# hsm_non_sec_secure register map
Vendor: Texas Instruments
Peripheral module from a debugger description file (folder CC35X1E).
Registers are 32-bit, access per field, reset 0x0 unless marked. A register's access mark holds for its fields unless they carry their own. Offsets are as the file gives them; lines under a group give offsets from that group; [hi:lo] are bit positions; {n}, {i} and the like mark numbered series; 'fields as' and 'values as' point back to an identical list; <NAME> marks a mode.

## hsm_non_sec_secure
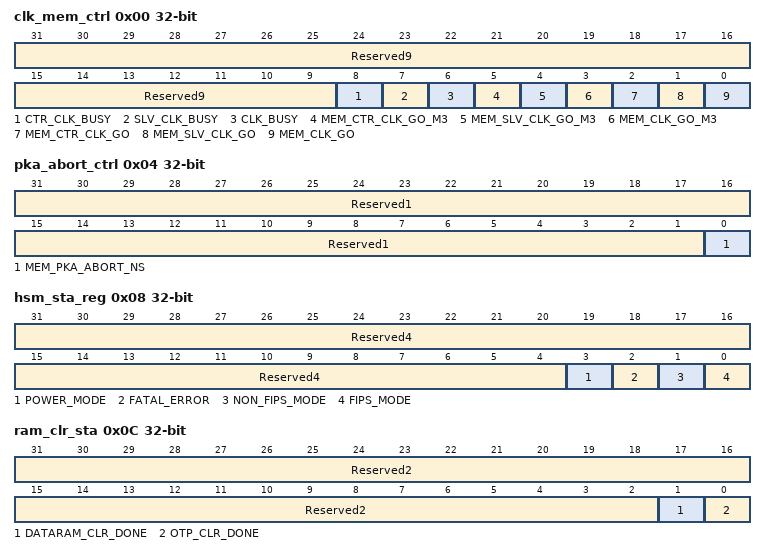
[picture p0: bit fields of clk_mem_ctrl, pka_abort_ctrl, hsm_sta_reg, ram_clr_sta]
0x00 clk_mem_ctrl — This register is used for enabling clock to the module
  [31:9] Reserved9 ro — Reads to this field return zero, writes to this field are ignored.
  [8] CTR_CLK_BUSY ro — When 1b, indicates that the counter clock domain is active. This signal is always asserted (set to '1'), except when the counter module is in reset (ctr_reset_n set to '0').
  [7] SLV_CLK_BUSY ro — When 1b indicates the Host interface is active and busy with Host bus transfers.
  [6] CLK_BUSY ro — when 1b, indicates that the module is active and busy with processing data and tokens.
  [5] MEM_CTR_CLK_GO_M3 rw — Write this bit to enable counter clock
    0=DIS (Write 0b to disable clock); 1=EN (Write 1b to enable clock)
  [4] MEM_SLV_CLK_GO_M3 rw — Write this bit to enable host interface clock
    1=EN (Write 1b to enable clock); 0=DIS (Write 0b to disable clock)
  [3] MEM_CLK_GO_M3 rw — M3 writes this bit to enable clock to the module
    values as MEM_CTR_CLK_GO_M3
  [2] MEM_CTR_CLK_GO rw — Write this bit to enable counter clock
    values as MEM_CTR_CLK_GO_M3
  [1] MEM_SLV_CLK_GO rw — Write this bit to enable host interface clock
    values as MEM_SLV_CLK_GO_M3
  [0] MEM_CLK_GO rw — Write this bit to enable clock to the module
    values as MEM_SLV_CLK_GO_M3
0x04 pka_abort_ctrl — This register is used for aborting PKA operation.
  [31:1] Reserved1 ro — Reads to this field return zero, writes to this field are ignored.
  [0] MEM_PKA_ABORT_NS rw — Write 1 to this bit to abort PKA operation
    1=ABORT (Set to 1, to abort PKA operation)
0x08 hsm_sta_reg ro — This register provides EIP130 status
  [31:4] Reserved4 — Reads to this field return zero, writes to this field are ignored.
  [3] POWER_MODE — Power mode value 1'b1 indicates hsm is in sleep and value 1'b0 indicates hsm is out of sleep.
  [2] FATAL_ERROR — If active (set to 1b), EIP130 detected a fatal error and stops operation. fatal error can happen when CRC on firmware ROM fails or selftest fails.
  [1] NON_FIPS_MODE — If active (set to 1b), EIP130 is in NON-FIPS mode
  [0] FIPS_MODE — If active (set to 1b), EIP130 is in FIPS mode
0x0C ram_clr_sta ro — This register stores status of asset clear indication.
  [31:2] Reserved2 — Reads to this field return zero, writes to this field are ignored.
  [1] DATARAM_CLR_DONE — If active (set to 1b), it indicates that auto clear of Dataram on reset release has been completed.
  [0] OTP_CLR_DONE — If active (set to 1b), it indicates that auto clear of OTP on reset release has been completed.
